# ADuCM410 register map
Vendor: Analog Devices; Series: ADuCM410; File version: 1p0
CPU: CM33 r0p1, little endian, MPU, FPU, 3 interrupt priority bits
Registers are 32-bit, read-write, reset 0x0 unless marked. A register's access mark holds for its fields unless they carry their own. Offsets are from the block's base; [hi:lo] are bit positions; {n}, {i} and the like mark numbered series.

## D2D0 — Serial Peripheral Interface
Base 0x40024000
Same registers: D2D1 0x40028000, SPI0 0x40054000, SPI1 0x40058000, SPI2 0x4005C000
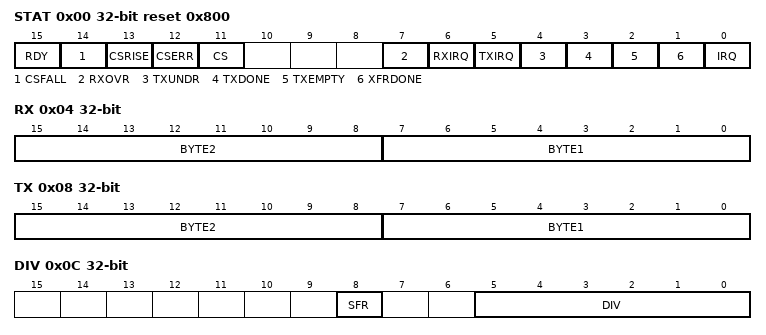
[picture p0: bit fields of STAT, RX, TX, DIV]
0x00 STAT reset 0x800 — Status
  [15] RDY range 0x00000000..0x00000001 — Detected an Edge on Ready Indicator for Flow-control
  [14] CSFALL range 0x00000000..0x00000001 — Detected a Falling Edge on CS, in Slave CON Mode
  [13] CSRISE range 0x00000000..0x00000001 — Detected a Rising Edge on CS, in Slave CON Mode
  [12] CSERR range 0x00000000..0x00000001 — Detected a CS Error Condition in Slave Mode
  [11] CS ro — CS Status
  [7] RXOVR range 0x00000000..0x00000001 — SPI Rx FIFO Overflow
  [6] RXIRQ range 0x00000000..0x00000001 — SPI Rx IRQ
  [5] TXIRQ range 0x00000000..0x00000001 — SPI Tx IRQ
  [4] TXUNDR range 0x00000000..0x00000001 — SPI Tx FIFO Underflow
  [3] TXDONE range 0x00000000..0x00000001 — SPI Tx Done in Read Command Mode
  [2] TXEMPTY range 0x00000000..0x00000001 — SPI Tx FIFO Empty Interrupt
  [1] XFRDONE range 0x00000000..0x00000001 — SPI Transfer Completion
  [0] IRQ ro — SPI Interrupt Status
0x04 RX — Receive
  [15:8] BYTE2 ro — 8-bit Receive Buffer, Used Only in DMA Modes
  [7:0] BYTE1 ro — 8-bit Receive Buffer
0x08 TX — Transmit
  [15:8] BYTE2 wo range 0x00000000..0x000000FF — 8-bit Transmit Buffer, Used Only in DMA Modes
  [7:0] BYTE1 wo range 0x00000000..0x000000FF — 8-bit Transmit Buffer
0x0C DIV — SPI Baud Rate Selection
  [8] SFR range 0x00000000..0x00000001 — Slave Free Run Mode
  [5:0] DIV range 0x00000000..0x0000003F — SPI Clock Divider
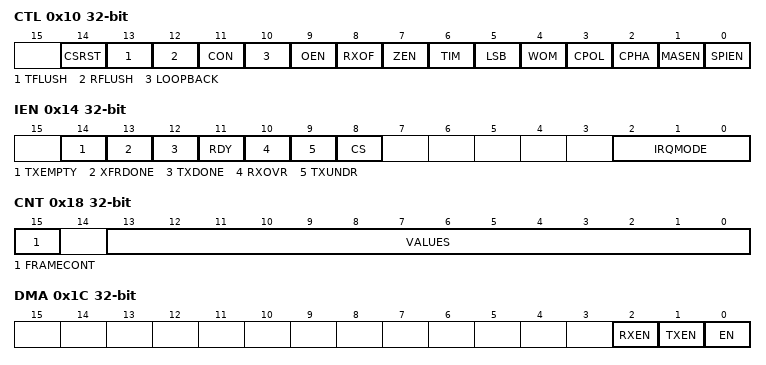
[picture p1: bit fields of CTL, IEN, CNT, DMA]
0x10 CTL — SPI Configuration 1
  [14] CSRST range 0x00000000..0x00000001 — Reset Mode for CS Error Bit
  [13] TFLUSH range 0x00000000..0x00000001 — SPI Tx FIFO Flush Enable
  [12] RFLUSH range 0x00000000..0x00000001 — SPI Rx FIFO Flush Enable
  [11] CON range 0x00000000..0x00000001 — Continuous Transfer Enable
  [10] LOOPBACK range 0x00000000..0x00000001 — Loopback Enable
  [9] OEN range 0x00000000..0x00000001 — Slave MISO Output Enable
  [8] RXOF range 0x00000000..0x00000001 — RX Overflow Overwrite Enable
  [7] ZEN range 0x00000000..0x00000001 — Transmit Zeros Enable
  [6] TIM range 0x00000000..0x00000001 — SPI Transfer and Interrupt Mode
  [5] LSB range 0x00000000..0x00000001 — LSB First Transfer Enable
  [4] WOM range 0x00000000..0x00000001 — SPI Wired or Mode
  [3] CPOL range 0x00000000..0x00000001 — Serial Clock Polarity
  [2] CPHA range 0x00000000..0x00000001 — Serial Clock Phase Mode
  [1] MASEN range 0x00000000..0x00000001 — Master Mode Enable
  [0] SPIEN range 0x00000000..0x00000001 — SPI Enable
0x14 IEN — SPI Configuration 2
  [14] TXEMPTY range 0x00000000..0x00000001 — Tx-FIFO Empty Interrupt Enable
  [13] XFRDONE range 0x00000000..0x00000001 — SPI Transfer Completion Interrupt Enable
  [12] TXDONE range 0x00000000..0x00000001 — SPI Transmit Done Interrupt Enable
  [11] RDY range 0x00000000..0x00000001 — Ready Signal Edge Interrupt Enable
  [10] RXOVR range 0x00000000..0x00000001 — Rx-overflow Interrupt Enable
  [9] TXUNDR range 0x00000000..0x00000001 — Tx-underflow Interrupt Enable
  [8] CS range 0x00000000..0x00000001 — Enable Interrupt on Every CS Edge in Slave CON Mode
  [2:0] IRQMODE — SPI IRQ Mode Bits
    {v}=TX{v+1}RX{v+1} (Interrupt Occurs After {v+1} Byte is Transfered or Received) (v=0..7)
0x18 CNT — Transfer Byte Count
  [15] FRAMECONT range 0x00000000..0x00000001 — Continue Frame
  [13:0] VALUES range 0x00000000..0x00003FFF — Transfer Byte Count
0x1C DMA — SPI DMA Enable
  [2] RXEN range 0x00000000..0x00000001 — Enable Receive DMA Request
  [1] TXEN range 0x00000000..0x00000001 — Enable Transmit DMA Request
  [0] EN range 0x00000000..0x00000001 — Enable DMA for Data Transfer
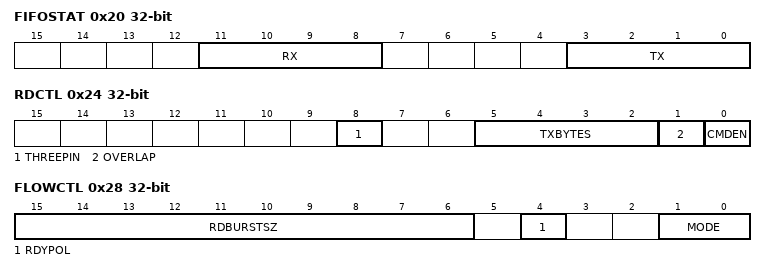
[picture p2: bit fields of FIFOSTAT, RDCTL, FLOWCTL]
0x20 FIFOSTAT — FIFO Status
  [11:8] RX ro — SPI Rx FIFO Status
    0=EMPTY (Rx FIFO Empty); 1=ONE (1 Valid Byte/half-word in Rx FIFO); 2=TWO (2 Valid Bytes/half-words in Rx FIFO); 3=THREE (3 Valid Bytes/half-words in Rx FIFO); 4=FOUR (4 Valid Bytes/half-words in Rx FIFO); 5=FIVE (5 Valid Bytes/half-words in Rx FIFO); 6=SIX (6 Valid Bytes/half-words in Rx FIFO); 7=SEVEN (7 Valid Bytes/half-words in Rx FIFO); 8=FULL (8 Valid Bytes/half-words in Rx FIFO (Rx FIFO Full))
  [3:0] TX ro — SPI Tx FIFO Status
    0=EMPTY (Tx FIFO Empty); 1=ONE (1 Valid Byte/half-word in Tx FIFO); 2=TWO (2 Valid Bytes/half-words in Tx FIFO); 3=THREE (3 Valid Bytes/half-words in Tx FIFO); 4=FOUR (4 Valid Bytes/half-words in Tx FIFO); 5=FIVE (5 Valid Bytes/half-words in Tx FIFO); 6=SIX (6 Valid Bytes/half-words in Tx FIFO); 7=SEVEN (7 Valid Bytes/half-words in Tx FIFO); 8=FULL (8 Valid Bytes/half-words in Tx FIFO (Tx FIFO Full))
0x24 RDCTL — Read Control
  [8] THREEPIN range 0x00000000..0x00000001 — Three Pin SPI Mode
  [5:2] TXBYTES range 0x00000000..0x0000000F — Transmit Byte Count Minus 1 for Read Command
  [1] OVERLAP range 0x00000000..0x00000001 — Tx/Rx Overlap Mode
  [0] CMDEN range 0x00000000..0x00000001 — Read Command Enable
0x28 FLOWCTL — Flow Control
  [15:6] RDBURSTSZ range 0x00000000..0x000003FF — Read Data Burst Size Minus 1
  [4] RDYPOL — Polarity of RDY/MISO Line
    0=HIGH (Polarity is Active HIGH. SPI Master Waits Until RDY/MISO Becomes HIGH.); 1=LOW (Polarity is Active LOW. SPI Master Waits Until RDY/MISO Becomes LOW.)
  [1:0] MODE — Flow Control Mode
    0=DISABLE (Flow Control is Disabled.); 1=TIMER (Flow Control is Based on Timer (WAIT_TMR).); 2=RDY (Flow Control is Based on RDY Signal.); 3=MISO (Flow Control is Based on MISO Pin.)
0x2C WAITTMR — Wait Timer for Flow Control
  [15:0] TRIMS range 0x00000000..0x0000FFFF — Wait Timer for Flow-control
0x34 CSOVERRIDE — Chip-Select Override
  [1:0] CTL — CS Override Control
    0=NOTFORCE (CS is Not Forced.); 1=FORCETO1 (CS is Forced to Drive 1'b1.); 2=FORCETO0 (CS is Forced to Drive 1'b0.)
